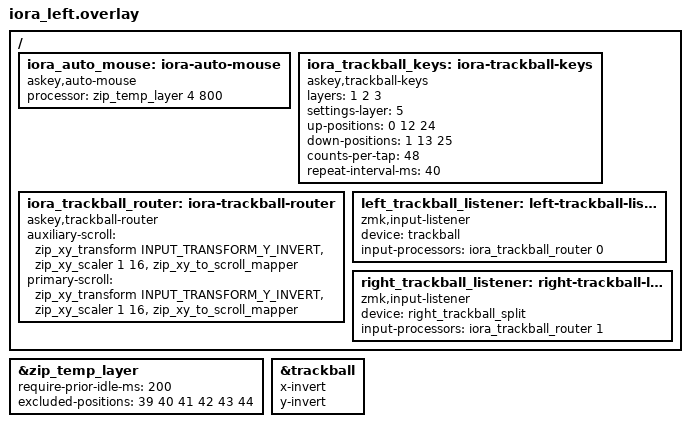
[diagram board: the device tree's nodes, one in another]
#include <dt-bindings/zmk/input_transform.h>
#include <input/processors.dtsi>
#include "iora.dtsi"

/ {
    iora_auto_mouse: iora-auto-mouse {
        compatible = "askey,auto-mouse";
        #input-processor-cells = <0>;
        processor = <&zip_temp_layer 4 800>;
    };

    iora_trackball_keys: iora-trackball-keys {
        compatible = "askey,trackball-keys";
        #input-processor-cells = <0>;
        layers = <1 2 3>;
        settings-layer = <5>;
        up-positions = <0 12 24>;
        down-positions = <1 13 25>;
        counts-per-tap = <48>;
        repeat-interval-ms = <40>;
    };

    iora_trackball_router: iora-trackball-router {
        compatible = "askey,trackball-router";
        #input-processor-cells = <1>;
        auxiliary-scroll = <&zip_xy_transform INPUT_TRANSFORM_Y_INVERT>,
                           <&zip_xy_scaler 1 16>,
                           <&zip_xy_to_scroll_mapper>;
        primary-scroll = <&zip_xy_transform INPUT_TRANSFORM_Y_INVERT>,
                         <&zip_xy_scaler 1 16>,
                         <&zip_xy_to_scroll_mapper>;
    };

    left_trackball_listener: left-trackball-listener {
        compatible = "zmk,input-listener";
        device = <&trackball>;
        input-processors = <&iora_trackball_router 0>;
    };

    right_trackball_listener: right-trackball-listener {
        compatible = "zmk,input-listener";
        device = <&right_trackball_split>;
        input-processors = <&iora_trackball_router 1>;
    };
};

&zip_temp_layer {
    require-prior-idle-ms = <200>;
    excluded-positions = <39 40 41 42 43 44>; /* Left and right thumb clusters */
};

&trackball {
    x-invert;
    y-invert;
};
